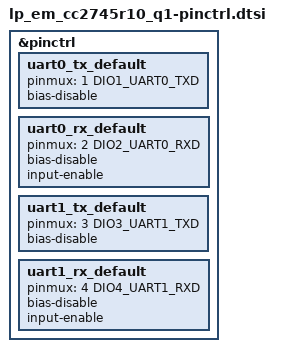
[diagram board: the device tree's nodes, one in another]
/*
 * Copyright (c) 2025 Texas Instruments Incorporated
 * Copyright (c) 2024 BayLibre, SAS
 *
 * SPDX-License-Identifier: Apache-2.0
 */

#include <zephyr/dt-bindings/pinctrl/cc27xx-pinctrl.h>

&pinctrl {
	/* UART0 */
	uart0_tx_default: uart0_tx_default {
		pinmux = <1 DIO1_UART0_TXD>;
		bias-disable;
	};
	uart0_rx_default: uart0_rx_default {
		pinmux = <2 DIO2_UART0_RXD>;
		bias-disable;
		input-enable;
	};

	/* UART1 */
	uart1_tx_default: uart1_tx_default {
		pinmux = <3 DIO3_UART1_TXD>;
		bias-disable;
	};
	uart1_rx_default: uart1_rx_default {
		pinmux = <4 DIO4_UART1_RXD>;
		bias-disable;
		input-enable;
	};
};
